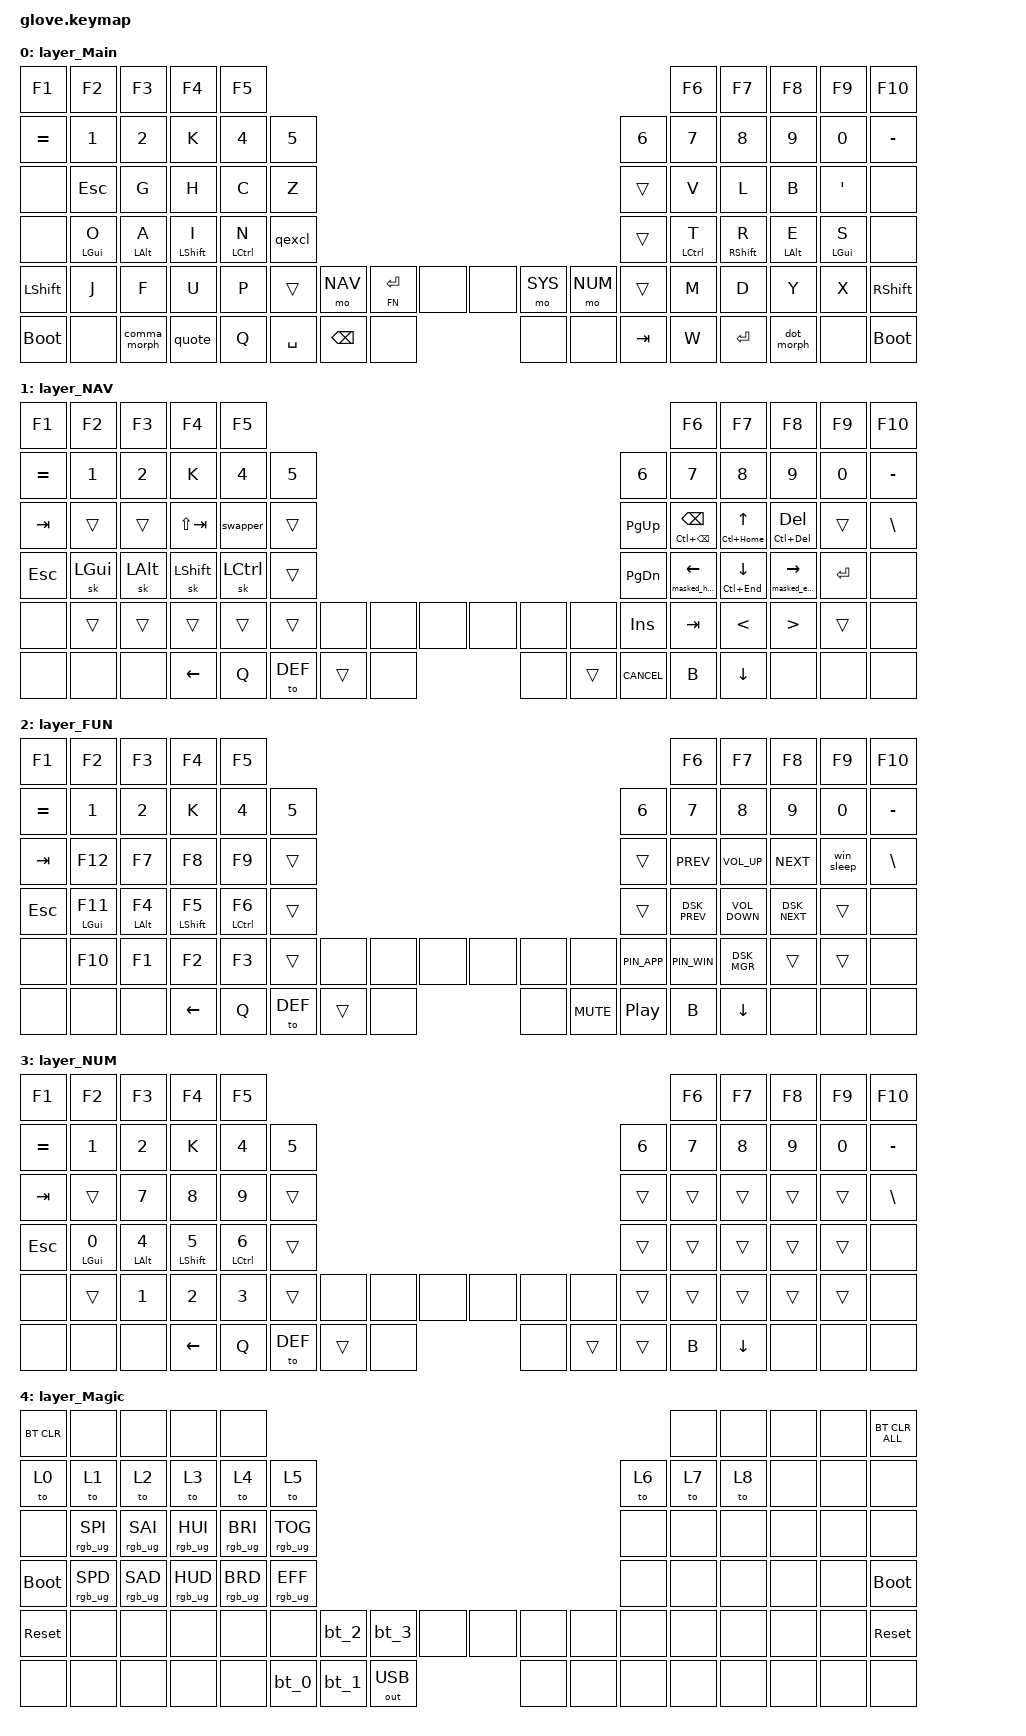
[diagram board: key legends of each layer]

/*
 * Copyright (c) 2020 The ZMK Contributors
 * Copyright (c) 2023 Innaworks Development Limited, trading as MoErgo
 *
 * SPDX-License-Identifier: MIT
 */


/* THIS FILE WAS GENERATED BY GLOVE80 LAYOUT EDITOR
 *
 * This file was generated automatically. You may or may not want to
 * edit it directly.
 */

#include <behaviors.dtsi>
/* Include all behavior includes needed */
#include <dt-bindings/zmk/outputs.h>
#include <dt-bindings/zmk/keys.h>
#include <dt-bindings/zmk/bt.h>
#include <dt-bindings/zmk/rgb.h>

/* Automatically generated layer name #define */
#define LAYER_Main 0
#define LAYER_NAV 1
#define LAYER_FUN 2
#define LAYER_NUM 3
#define LAYER_Magic 4

/* To deal with the situation where there is no Lower layer, to keep &lower happy */
#ifndef LAYER_Lower
#define LAYER_Lower 5
#endif

/* Custom Device-tree */



/* Glove80 system behavior & macros */
/ {
    behaviors {
        // For the "layer" key, it'd nice to be able to use it as either a shift or a toggle.
        // Configure it as a tap dance, so the first tap (or hold) is a &mo and the second tap is a &to
        lower: lower {
            compatible = "zmk,behavior-tap-dance";
            label = "LAYER_TAP_DANCE";
            #binding-cells = <0>;
            tapping-term-ms = <200>;
            bindings = <&mo LAYER_Lower>, <&to LAYER_Lower>;
        };
    };
};

/ {
    macros {
        rgb_ug_status_macro: rgb_ug_status_macro {
            label = "RGB_UG_STATUS";
            compatible = "zmk,behavior-macro";
            #binding-cells = <0>;
            bindings
                = <&rgb_ug RGB_STATUS>;
        };
    };
};


/ {
#ifdef BT_DISC_CMD
    behaviors {
        bt_0: bt_0 {
            compatible = "zmk,behavior-tap-dance";
            label = "BT_0";
            #binding-cells = <0>;
            tapping-term-ms = <200>;
            bindings = <&bt_select_0>, <&bt BT_DISC 0>;
        };
        bt_1: bt_1 {
            compatible = "zmk,behavior-tap-dance";
            label = "BT_1";
            #binding-cells = <0>;
            tapping-term-ms = <200>;
            bindings = <&bt_select_1>, <&bt BT_DISC 1>;
        };
        bt_2: bt_2 {
            compatible = "zmk,behavior-tap-dance";
            label = "BT_2";
            #binding-cells = <0>;
            tapping-term-ms = <200>;
            bindings = <&bt_select_2>, <&bt BT_DISC 2>;
        };
        bt_3: bt_3 {
            compatible = "zmk,behavior-tap-dance";
            label = "BT_3";
            #binding-cells = <0>;
            tapping-term-ms = <200>;
            bindings = <&bt_select_3>, <&bt BT_DISC 3>;
        };
    };
    macros {
        bt_select_0: bt_select_0 {
            label = "BT_SELECT_0";
            compatible = "zmk,behavior-macro";
            #binding-cells = <0>;
            bindings
                = <&out OUT_BLE>,
                  <&bt BT_SEL 0>;
        };
        bt_select_1: bt_select_1 {
            label = "BT_SELECT_1";
            compatible = "zmk,behavior-macro";
            #binding-cells = <0>;
            bindings
                = <&out OUT_BLE>,
                  <&bt BT_SEL 1>;
        };
        bt_select_2: bt_select_2 {
            label = "BT_SELECT_2";
            compatible = "zmk,behavior-macro";
            #binding-cells = <0>;
            bindings
                = <&out OUT_BLE>,
                  <&bt BT_SEL 2>;
        };
        bt_select_3: bt_select_3 {
            label = "BT_SELECT_3";
            compatible = "zmk,behavior-macro";
            #binding-cells = <0>;
            bindings
                = <&out OUT_BLE>,
                  <&bt BT_SEL 3>;
        };
    };
#else
    macros {
        bt_0: bt_0 {
            label = "BT_0";
            compatible = "zmk,behavior-macro";
            #binding-cells = <0>;
            bindings
                = <&out OUT_BLE>,
                  <&bt BT_SEL 0>;
        };
        bt_1: bt_1 {
            label = "BT_1";
            compatible = "zmk,behavior-macro";
            #binding-cells = <0>;
            bindings
                = <&out OUT_BLE>,
                  <&bt BT_SEL 1>;
        };
        bt_2: bt_2 {
            label = "BT_2";
            compatible = "zmk,behavior-macro";
            #binding-cells = <0>;
            bindings
                = <&out OUT_BLE>,
                  <&bt BT_SEL 2>;
        };
        bt_3: bt_3 {
            label = "BT_3";
            compatible = "zmk,behavior-macro";
            #binding-cells = <0>;
            bindings
                = <&out OUT_BLE>,
                  <&bt BT_SEL 3>;
        };
    };
#endif
};

&sk {  // sticky-key config
    release-after-ms = <900>;  // release after 0.6s
    quick-release;             // no double capitalization when rolling keys
};

&sl {  // sticky-layer config
    ignore-modifiers;          // allow chording sticky mods & layers
};

&lt {  // layer-tap config
    flavor = "balanced";
    tapping-term-ms = <200>;
    quick-tap-ms = <QUICK_TAP_MS>;
};

/ {
    behaviors {
        magic: magic {
            compatible = "zmk,behavior-hold-tap";
            label = "MAGIC_HOLD_TAP";
            #binding-cells = <2>;
            flavor = "tap-preferred";
            tapping-term-ms = <200>;
            bindings = <&mo>, <&rgb_ug_status_macro>;
        };
    };
};

/* #define for key positions */
#define POS_LH_T1 52
#define POS_LH_T2 53
#define POS_LH_T3 54
#define POS_LH_T4 69
#define POS_LH_T5 70
#define POS_LH_T6 71
#define POS_LH_C1R2 15
#define POS_LH_C1R3 27
#define POS_LH_C1R4 39
#define POS_LH_C1R5 51
#define POS_LH_C2R1 4
#define POS_LH_C2R2 14
#define POS_LH_C2R3 26
#define POS_LH_C2R4 38
#define POS_LH_C2R5 50
#define POS_LH_C2R6 68
#define POS_LH_C3R1 3
#define POS_LH_C3R2 13
#define POS_LH_C3R3 25
#define POS_LH_C3R4 37
#define POS_LH_C3R5 49
#define POS_LH_C3R6 67
#define POS_LH_C4R1 2
#define POS_LH_C4R2 12
#define POS_LH_C4R3 24
#define POS_LH_C4R4 36
#define POS_LH_C4R5 48
#define POS_LH_C4R6 66
#define POS_LH_C5R1 1
#define POS_LH_C5R2 11
#define POS_LH_C5R3 23
#define POS_LH_C5R4 35
#define POS_LH_C5R5 47
#define POS_LH_C5R6 65
#define POS_LH_C6R1 0
#define POS_LH_C6R2 10
#define POS_LH_C6R3 22
#define POS_LH_C6R4 34
#define POS_LH_C6R5 46
#define POS_LH_C6R6 64
#define POS_RH_T1 57
#define POS_RH_T2 56
#define POS_RH_T3 55
#define POS_RH_T4 74
#define POS_RH_T5 73
#define POS_RH_T6 72
#define POS_RH_C1R2 16
#define POS_RH_C1R3 28
#define POS_RH_C1R4 40
#define POS_RH_C1R5 58
#define POS_RH_C2R1 5
#define POS_RH_C2R2 17
#define POS_RH_C2R3 29
#define POS_RH_C2R4 41
#define POS_RH_C2R5 59
#define POS_RH_C2R6 75
#define POS_RH_C3R1 6
#define POS_RH_C3R2 18
#define POS_RH_C3R3 30
#define POS_RH_C3R4 42
#define POS_RH_C3R5 60
#define POS_RH_C3R6 76
#define POS_RH_C4R1 7
#define POS_RH_C4R2 19
#define POS_RH_C4R3 31
#define POS_RH_C4R4 43
#define POS_RH_C4R5 61
#define POS_RH_C4R6 77
#define POS_RH_C5R1 8
#define POS_RH_C5R2 20
#define POS_RH_C5R3 32
#define POS_RH_C5R4 44
#define POS_RH_C5R5 62
#define POS_RH_C5R6 78
#define POS_RH_C6R1 9
#define POS_RH_C6R2 21
#define POS_RH_C6R3 33
#define POS_RH_C6R4 45
#define POS_RH_C6R5 63
#define POS_RH_C6R6 79

#define LC1  4  // left-ceiling row
#define LC2  3
#define LC3  2
#define LC4  1
#define LC5  0

#define RC1  5  // right-ceiling row
#define RC2  6
#define RC3  7
#define RC4  8
#define RC5  9

#define LN0 15  // left-number row
#define LN1 14
#define LN2 13
#define LN3 12
#define LN4 11
#define LN5 10

#define RN0 16  // right-number row
#define RN1 17
#define RN2 18
#define RN3 19
#define RN4 20
#define RN5 21

#define LT0 27  // left-top row
#define LT1 26
#define LT2 25
#define LT3 24
#define LT4 23
#define LT5 22

#define RT0 28  // right-top row
#define RT1 29
#define RT2 30
#define RT3 31
#define RT4 32
#define RT5 33

#define LM0 39  // left-middle row
#define LM1 38
#define LM2 37
#define LM3 36
#define LM4 35
#define LM5 34

#define RM0 40  // right-middle row
#define RM1 41
#define RM2 42
#define RM3 43
#define RM4 44
#define RM5 45

#define LB0 51  // left-bottom row
#define LB1 50
#define LB2 49
#define LB3 48
#define LB4 47
#define LB5 46

#define RB0 58  // right-bottom row
#define RB1 59
#define RB2 60
#define RB3 61
#define RB4 62
#define RB5 63

#define LF1 68  // left-floor row
#define LF2 67
#define LF3 66
#define LF4 65
#define LF5 64

#define RF1 75  // right-floor row
#define RF2 76
#define RF3 77
#define RF4 78
#define RF5 79

#define LH0 71  // left thumb keys
#define LH1 70
#define LH2 69
#define LH3 54
#define LH4 53
#define LH5 52

#define RH0 72  // right thumb keys
#define RH1 73
#define RH2 74
#define RH3 55
#define RH4 56
#define RH5 57



/* Custom Defined Behaviors */
/ {


behaviors {
        hml: hml { compatible = "zmk,behavior-hold-tap"; #binding-cells = <2>; flavor = "balanced"; tapping-term-ms = <280>; quick-tap-ms = <175>; require-prior-idle-ms = <350>; bindings = <&kp>, <&kp>; hold-trigger-key-positions = <28 29 30 31 32 40 41 42 43 44 58 59 60 61 62 75 76 77 78 79 69 70 71 72 73 74>; hold-trigger-on-release; };
hmr: hmr { compatible = "zmk,behavior-hold-tap"; #binding-cells = <2>; flavor = "balanced"; tapping-term-ms = <280>; quick-tap-ms = <175>; require-prior-idle-ms = <350>; bindings = <&kp>, <&kp>; hold-trigger-key-positions = <27 26 25 24 23 39 38 37 36 35 51 50 49 48 47 68 67 66 65 64 15 14 13 12 11 10 69 70 71 72 73 74>; hold-trigger-on-release; };

hml_repeat: hml_repeat { compatible = "zmk,behavior-hold-tap"; #binding-cells = <2>; flavor = "balanced"; tapping-term-ms = <280>; quick-tap-ms = <175>; require-prior-idle-ms = <350>; bindings = <&kp>, <&key_repeat>; hold-trigger-key-positions = <28 29 30 31 32 40 41 42 43 44 58 59 60 61 62 75 76 77 78 79 69 70 71 72 73 74>; hold-trigger-on-release; };
hmr_lpar_lt: hmr_lpar_lt { compatible = "zmk,behavior-hold-tap"; #binding-cells = <2>; flavor = "balanced"; tapping-term-ms = <280>; quick-tap-ms = <175>; require-prior-idle-ms = <350>; bindings = <&kp>, <&lpar_lt>; hold-trigger-key-positions = <27 26 25 24 23 39 38 37 36 35 51 50 49 48 47 68 67 66 65 64 15 14 13 12 11 10 69 70 71 72 73 74>; hold-trigger-on-release; };
hmr_rpar_gt: hmr_rpar_gt { compatible = "zmk,behavior-hold-tap"; #binding-cells = <2>; flavor = "balanced"; tapping-term-ms = <280>; quick-tap-ms = <175>; require-prior-idle-ms = <350>; bindings = <&kp>, <&rpar_gt>; hold-trigger-key-positions = <27 26 25 24 23 39 38 37 36 35 51 50 49 48 47 68 67 66 65 64 15 14 13 12 11 10 69 70 71 72 73 74>; hold-trigger-on-release; };
# 336 "/app/example.cpp"
&mt { flavor = "tap-preferred"; tapping-term-ms = <220>; quick-tap-ms = <220>; hold-trigger-key-positions = <0>; };
mt_home: mt_home { compatible = "zmk,behavior-hold-tap"; #binding-cells = <2>; bindings = <&masked_home>, <&kp>; flavor = "tap-preferred"; tapping-term-ms = <220>; quick-tap-ms = <220>; hold-trigger-key-positions = <0>; };
mt_end: mt_end { compatible = "zmk,behavior-hold-tap"; #binding-cells = <2>; bindings = <&masked_end>, <&kp>; flavor = "tap-preferred"; tapping-term-ms = <220>; quick-tap-ms = <220>; hold-trigger-key-positions = <0>; };
# 353 "/app/example.cpp"
masked_home: masked_home { compatible = "zmk,behavior-mod-morph"; #binding-cells = <0>; bindings = <&kp HOME>, <&kp HOME>; mods = <(MOD_LCTL)>; };
masked_end: masked_end { compatible = "zmk,behavior-mod-morph"; #binding-cells = <0>; bindings = <&kp END>, <&kp END>; mods = <(MOD_LCTL)>; };

smart_shft: smart_shft { compatible = "zmk,behavior-mod-morph"; #binding-cells = <0>; bindings = <&sk LSHFT>, <&caps_word>; mods = <(MOD_LSFT)>; };

&caps_word {
    /delete-property/ ignore-modifiers;
};

smart_num: smart_num { compatible = "zmk,behavior-hold-tap"; #binding-cells = <2>; flavor = "balanced"; tapping-term-ms = <200>; quick-tap-ms = <175>; bindings = <&mo>, <&num_dance>; };

num_dance: num_dance { compatible = "zmk,behavior-tap-dance"; #binding-cells = <0>; tapping-term-ms = <200>; bindings = <&num_word>, <&sl Layer_NUM>; };

&num_word {
    layers = <Layer_NUM>;
    continue-list = <BSPC DEL DOT COMMA PLUS MINUS STAR FSLH EQUAL>;
};

smart_mouse: smart_mouse { compatible = "zmk,behavior-tri-state"; #binding-cells = <0>; bindings = <&tog MOUSE>, <&none>, <&tog MOUSE>; ignored-key-positions = <26 24 28 29 30 31 32 41 42 43 59 60 61 72 73>; ignored-layers = <MOUSE>; };
# 394 "/app/example.cpp"
swapper: swapper { compatible = "zmk,behavior-tri-state"; #binding-cells = <0>; bindings = <&kt LALT>, <&kp TAB>, <&kt LALT>; ignored-key-positions = <25>; };

sls: sls { compatible = "zmk,behavior-sticky-key"; #binding-cells = <1>; release-after-ms = <1000>; bindings = <&uc_shift>; ignore-modifiers; };

uc_shift: uc_shift { compatible = "zmk,behavior-macro"; #binding-cells = <0>; wait-ms = <0>; tap-ms = <1>; bindings = <&macro_press &mo UC &kp LSHFT> , <&macro_pause_for_release> , <&macro_release &mo UC &kp LSHFT>; };
# 421 "/app/example.cpp"
comma_morph: comma_morph { compatible = "zmk,behavior-mod-morph"; #binding-cells = <0>; mods = <(MOD_LSFT|MOD_RSFT)>; bindings = <&kp COMMA>, <&comma_inner_morph>; };
comma_inner_morph: comma_inner_morph { compatible = "zmk,behavior-mod-morph"; #binding-cells = <0>; mods = <(MOD_LCTL|MOD_RCTL)>; bindings = <&kp SEMICOLON>, <&kp LESS_THAN>; };

dot_morph: dot_morph { compatible = "zmk,behavior-mod-morph"; #binding-cells = <0>; mods = <(MOD_LSFT|MOD_RSFT)>; bindings = <&kp DOT>, <&dot_inner_morph>; };
dot_inner_morph: dot_inner_morph { compatible = "zmk,behavior-mod-morph"; #binding-cells = <0>; mods = <(MOD_LCTL|MOD_RCTL)>; bindings = <&kp COLON>, <&kp GREATER_THAN>; };

qexcl: qexcl { compatible = "zmk,behavior-mod-morph"; #binding-cells = <0>; mods = <(MOD_LSFT|MOD_RSFT)>; bindings = <&kp QMARK>, <&kp EXCL>; };
quote: quote { compatible = "zmk,behavior-mod-morph"; #binding-cells = <0>; mods = <(MOD_LSFT|MOD_RSFT)>; bindings = <&kp LS(SINGLE_QUOTE)>, <&kp SINGLE_QUOTE>; };

lpar_lt: lpar_lt { compatible = "zmk,behavior-mod-morph"; #binding-cells = <0>; mods = <(MOD_LSFT|MOD_RSFT)>; bindings = <&kp LPAR>, <&kp LT>; };
rpar_gt: rpar_gt { compatible = "zmk,behavior-mod-morph"; #binding-cells = <0>; mods = <(MOD_LSFT|MOD_RSFT)>; bindings = <&kp RPAR>, <&kp GT>; };

lt_spc: lt_spc { compatible = "zmk,behavior-hold-tap"; #binding-cells = <2>; flavor = "balanced"; tapping-term-ms = <200>; quick-tap-ms = <175>; bindings = <&mo>, <&spc_morph>; };

spc_morph: spc_morph { compatible = "zmk,behavior-mod-morph"; #binding-cells = <0>; mods = <(MOD_LSFT|MOD_RSFT)>; bindings = <&kp SPACE>, <&dot_spc>; };
dot_spc: dot_spc { compatible = "zmk,behavior-macro"; #binding-cells = <0>; wait-ms = <0>; tap-ms = <5>; bindings = <&kp DOT &kp SPACE &sk LSHFT>; };

bs_del: bs_del { compatible = "zmk,behavior-mod-morph"; #binding-cells = <0>; bindings = <&kp BSPC>, <&kp DEL>; mods = <(MOD_LSFT|MOD_RSFT)>; keep-mods = <MOD_RSFT>; };

copy_cut: copy_cut { compatible = "zmk,behavior-tap-dance"; #binding-cells = <0>; tapping-term-ms = <200>; bindings = <&kp LC(INS)>, <&kp LC(X)>; };

win_sleep: win_sleep { compatible = "zmk,behavior-macro"; #binding-cells = <0>; wait-ms = <500>; tap-ms = <50>; bindings = <&kp LG(X) &kp U &kp S>; };
};


/ { conditional_layers { compatible = "zmk,conditional-layers"; tri_layer { if-layers = <FN Layer_NUM>; then-layer = <SYS>; }; }; };

    //
    // Glove80 key positions index for positional hold-tap
    // - https://discord.com/channels/877392805654306816/937645688244826154/1066713913351221248
    // - https://media.discordapp.net/attachments/937645688244826154/1066713913133121556/image.png
    //
    // |------------------------|------------------------|
    // | LEFT_HAND_KEYS         |        RIGHT_HAND_KEYS |
    // |                        |                        |
    // |  0  1  2  3  4         |          5  6  7  8  9 |
    // | 10 11 12 13 14 15      |      16 17 18 19 20 21 |
    // | 22 23 24 25 26 27      |      28 29 30 31 32 33 |
    // | 34 35 36 37 38 39      |      40 41 42 43 44 45 |
    // | 46 47 48 49 50 51      |      58 59 60 61 62 63 |
    // | 64 65 66 67 68         |         75 76 77 78 79 |
    // |                69 52   |   57 74                |
    // |                 70 53  |  56 73                 |
    // |                  71 54 | 55 72                  |
    // |------------------------|------------------------|
    //

macros {



  // Function arrow: ->
  func_arrow: function_arrow {
    compatible = "zmk,behavior-macro";
    label = "FUNCTION_ARROW";
    #binding-cells = <0>;
    tap-ms = <0>;
    wait-ms = <0>;
    bindings
    = <&macro_tap &kp MINUS &kp GREATER_THAN>
    ;
  };

  and_short: and_short{
    compatible = "zmk,behavior-macro";
    label = "AND_SHORT";
    #binding-cells = <0>;
    tap-ms = <0>;
    wait-ms = <0>;
    bindings
    = <&macro_tap &kp AMPERSAND &kp AMPERSAND>
    ;
  };

  or_short: or_short{
    compatible = "zmk,behavior-macro";
    label = "OR_SHORT";
    #binding-cells = <0>;
    tap-ms = <0>;
    wait-ms = <0>;
    bindings
    = <&macro_tap &kp PIPE &kp PIPE>
    ;
  };

  neq_short: neq_short{
    compatible = "zmk,behavior-macro";
    label = "NEQ_SHORT";
    #binding-cells = <0>;
    tap-ms = <0>;
    wait-ms = <0>;
    bindings
    = <&macro_tap &kp EXCLAMATION &kp EQUAL>
    ;
  };

  eq_short: eq_short{
      compatible = "zmk,behavior-macro";
      label = "EQ_SHORT";
      #binding-cells = <0>;
      tap-ms = <0>;
      wait-ms = <0>;
      bindings
      = <&macro_tap &kp EQUAL &kp EQUAL>
      ;
    };
};
combos {
    compatible = "zmk,combos";
 combo_esc { timeout-ms = <18>; bindings = <&kp ESC>; key-positions = <24 25>; layers = <Layer_Main Layer_NAV Layer_NUM>; require-prior-idle-ms = <150>; };
 combo_ret { timeout-ms = <18>; bindings = <&kp RETURN>; key-positions = <25 26>; layers = <Layer_Main Layer_NAV Layer_NUM>; require-prior-idle-ms = <150>; };
 combo_mouse { timeout-ms = <18>; bindings = <&smart_mouse>; key-positions = <24 26>; layers = <Layer_Main Layer_NAV Layer_NUM>; require-prior-idle-ms = <150>; };
 combo_tab { timeout-ms = <18>; bindings = <&hml LS(LALT) TAB>; key-positions = <36 37>; layers = <Layer_Main Layer_NAV Layer_NUM>; require-prior-idle-ms = <150>; };
 combo_repeat { timeout-ms = <18>; bindings = <&hml_repeat LS(LCTRL) 0>; key-positions = <37 38>; layers = <Layer_Main Layer_NAV Layer_NUM>; require-prior-idle-ms = <150>; };
 combo_cut { timeout-ms = <18>; bindings = <&kp LC(X)>; key-positions = <48 50>; layers = <Layer_Main Layer_NAV Layer_NUM>; require-prior-idle-ms = <150>; };
 combo_copy { timeout-ms = <18>; bindings = <&kp LC(INS)>; key-positions = <48 49>; layers = <Layer_Main Layer_NAV Layer_NUM>; require-prior-idle-ms = <150>; };
 combo_paste { timeout-ms = <18>; bindings = <&kp LS(INS)>; key-positions = <49 50>; layers = <Layer_Main Layer_NAV Layer_NUM>; require-prior-idle-ms = <150>; };
 combo_bspc { timeout-ms = <18>; bindings = <&kp BSPC>; key-positions = <29 30>; layers = <Layer_Main Layer_NAV Layer_NUM>; require-prior-idle-ms = <150>; };
 combo_del { timeout-ms = <18>; bindings = <&kp DEL>; key-positions = <30 31>; layers = <Layer_Main Layer_NAV Layer_NUM>; require-prior-idle-ms = <150>; };
 combo_lpar { timeout-ms = <18>; bindings = <&hmr_lpar_lt RS(LCTRL) 0>; key-positions = <41 42>; layers = <Layer_Main Layer_NUM>; require-prior-idle-ms = <150>; };
 combo_rpar { timeout-ms = <18>; bindings = <&hmr_rpar_gt RS(LALT) 0>; key-positions = <42 43>; layers = <Layer_Main Layer_NUM>; require-prior-idle-ms = <150>; };
 combo_lt { timeout-ms = <18>; bindings = <&kp LT>; key-positions = <41 42>; layers = <Layer_NAV>; require-prior-idle-ms = <150>; };
 combo_gt { timeout-ms = <18>; bindings = <&kp GT>; key-positions = <42 43>; layers = <Layer_NAV>; require-prior-idle-ms = <150>; };
 combo_lbkt { timeout-ms = <18>; bindings = <&kp LBKT>; key-positions = <59 60>; layers = <Layer_Main Layer_NUM>; require-prior-idle-ms = <150>; };
 combo_rbkt { timeout-ms = <18>; bindings = <&kp RBKT>; key-positions = <60 61>; layers = <Layer_Main Layer_NUM>; require-prior-idle-ms = <150>; };
 combo_lbrc { timeout-ms = <18>; bindings = <&kp LBRC>; key-positions = <59 60>; layers = <Layer_NAV>; require-prior-idle-ms = <150>; };
 combo_rbrc { timeout-ms = <18>; bindings = <&kp RBRC>; key-positions = <60 61>; layers = <Layer_NAV>; require-prior-idle-ms = <150>; };
 combo_grk { timeout-ms = <18>; bindings = <&sl UC>; key-positions = <29 31>; layers = <Layer_Main Layer_NAV Layer_NUM>; require-prior-idle-ms = <150>; };
 combo_cpgrk { timeout-ms = <18>; bindings = <&sls 0>; key-positions = <29 30 31>; layers = <Layer_Main Layer_NAV Layer_NUM>; require-prior-idle-ms = <150>; };
 combo_at { timeout-ms = <30>; bindings = <&kp AT>; key-positions = <24 36>; layers = <Layer_Main Layer_NAV Layer_NUM>; require-prior-idle-ms = <50>; };
 combo_hash { timeout-ms = <30>; bindings = <&kp HASH>; key-positions = <25 37>; layers = <Layer_Main Layer_NAV Layer_NUM>; require-prior-idle-ms = <50>; };
 combo_dllr { timeout-ms = <30>; bindings = <&kp DLLR>; key-positions = <26 38>; layers = <Layer_Main Layer_NAV Layer_NUM>; require-prior-idle-ms = <50>; };
 combo_prcnt { timeout-ms = <30>; bindings = <&kp PRCNT>; key-positions = <27 39>; layers = <Layer_Main Layer_NAV Layer_NUM>; require-prior-idle-ms = <50>; };
 combo_grave { timeout-ms = <30>; bindings = <&kp GRAVE>; key-positions = <36 48>; layers = <Layer_Main Layer_NAV Layer_NUM>; require-prior-idle-ms = <50>; };
 combo_bslh { timeout-ms = <30>; bindings = <&kp BSLH>; key-positions = <37 49>; layers = <Layer_Main Layer_NAV Layer_NUM>; require-prior-idle-ms = <50>; };
 combo_equal { timeout-ms = <30>; bindings = <&kp EQUAL>; key-positions = <38 50>; layers = <Layer_Main Layer_NAV Layer_NUM>; require-prior-idle-ms = <50>; };
 combo_tilde { timeout-ms = <30>; bindings = <&kp TILDE>; key-positions = <39 51>; layers = <Layer_Main Layer_NAV Layer_NUM>; require-prior-idle-ms = <50>; };
 combo_caret { timeout-ms = <30>; bindings = <&kp CARET>; key-positions = <28 40>; layers = <Layer_Main Layer_NAV Layer_NUM>; require-prior-idle-ms = <50>; };
 combo_plus { timeout-ms = <30>; bindings = <&kp PLUS>; key-positions = <29 41>; layers = <Layer_Main Layer_NAV Layer_NUM>; require-prior-idle-ms = <50>; };
 combo_star { timeout-ms = <30>; bindings = <&kp STAR>; key-positions = <30 42>; layers = <Layer_Main Layer_NAV Layer_NUM>; require-prior-idle-ms = <50>; };
 combo_amps { timeout-ms = <30>; bindings = <&kp AMPS>; key-positions = <31 43>; layers = <Layer_Main Layer_NAV Layer_NUM>; require-prior-idle-ms = <50>; };
 combo_under { timeout-ms = <30>; bindings = <&kp UNDER>; key-positions = <40 58>; layers = <Layer_Main Layer_NAV Layer_NUM>; require-prior-idle-ms = <50>; };
 combo_minus { timeout-ms = <30>; bindings = <&kp MINUS>; key-positions = <41 59>; layers = <Layer_Main Layer_NAV Layer_NUM>; require-prior-idle-ms = <50>; };
 combo_fslh { timeout-ms = <30>; bindings = <&kp FSLH>; key-positions = <42 60>; layers = <Layer_Main Layer_NAV Layer_NUM>; require-prior-idle-ms = <50>; };
 combo_pipe { timeout-ms = <30>; bindings = <&kp PIPE>; key-positions = <43 61>; layers = <Layer_Main Layer_NAV Layer_NUM>; require-prior-idle-ms = <50>; };
};

};

/* Automatically generated macro definitions */
/ {
    macros {
    
    };
};


/* Automatically generated keymap */
/ {
    keymap {
        compatible = "zmk,keymap";


        layer_Main {
            bindings = <
    //╭─────────────┬─────────────┬─────────────┬─────────────┬─────────────╮                                                                                                            ╭─────────────┬─────────────┬─────────────┬──────────────┬─────────────╮
     &kp F1         &kp F2        &kp F3       &kp F4        &kp F5                                                                                                                    &kp F6        &kp F7        &kp F8        &kp F9        &kp F10 
//├─────────────┼─────────────┼─────────────┼─────────────┼─────────────┼───────────╮                                                                                 ╭──────────────┼─────────────┼─────────────┼─────────────┼──────────────┼─────────────┤
     &kp EQUAL      &kp N1        &kp N2       &kp K         &kp N4        &kp N5                                                                                       &kp N6         &kp N7        &kp N8        &kp N9        &kp N0        &kp MINUS                
//╰─────────────┴─────────────┴─────────────┴─────────────┴─────────────┴───────────╯                                                                                 ╰──────────────┴─────────────┴─────────────┴─────────────┴──────────────┴─────────────╯
         
//╭─────────────┬──────────────┬─────────────┬─────────────┬─────────────┬────────────╮                                                                               ╭─────────────┬─────────────┬─────────────┬─────────────┬──────────────┬──────────────╮
    &none         &kp ESC        &kp G         &kp H         &kp C          &kp Z                                                                                          &trans       &kp V         &kp L         &kp B         &kp SQT       &none  
//├─────────────┤──────────────┼─────────────┼─────────────┼─────────────┼────────────┤                                                                               ├─────────────┼─────────────┼─────────────┼─────────────┼──────────────┼──────────────┤
    &none         &hml LGUI O    &hml LALT A   &hml LSHFT I  &hml LCTRL N   &qexcl                                                                                         &trans       &hmr LCTRL T  &hmr RSHFT R  &hmr LALT E   &hmr LGUI S   &none  
//├─────────────┤──────────────┼─────────────┼─────────────┼─────────────┼────────────┤ ╭──────────────┬─────────────┬───────╮╭────────┬──────────────┬─────────────╮ ├─────────────┼─────────────┼─────────────┼─────────────┼──────────────┼──────────────┤
    &kp LSHFT     &kp J          &kp F         &kp U         &kp P          &trans         &mo NAV       &lt FN RET    &none    &none     &mo SYS       &mo NUM           &trans        &kp M         &kp D         &kp Y         &kp X         &kp RSHFT  
//├─────────────┼──────────────┤─────────────┼─────────────┤─────────────┼────────────╯ ├──────────────┼─────────────┼───────┤├────────┼──────────────┼─────────────┤ ╰─────────────┼─────────────┼─────────────┤─────────────┼──────────────┤──────────────┤
    &bootloader   &none         &comma_morph   &quote        &kp Q                         &kp SPACE     &kp BACKSPACE &none    &none     &none         &kp TAB                         &kp W         &kp RET      &dot_morph     &none         &bootloader
//╰─────────────┴──────────────┴─────────────┴─────────────┴─────────────╯              ╰──────────────┴─────────────┴───────╯╰────────┴──────────────┴─────────────╯               ╰─────────────┴─────────────┴─────────────┴──────────────┴──────────────╯                                           
           >;
        };

        layer_NAV {      
                    bindings = <             
//╭──────╮ ╭─────────────┬─────────────┬─────────────┬─────────────┬─────────────╮ ╭──────╮ ╭─────────────┬─────────────┬─────────────┬─────────────┬─────────────╮ ╭──────╮
    \
                &kp F1    &kp F2 &kp F3 &kp F4 &kp F5                 &kp F6 &kp F7 &kp F8 &kp F9 &kp F10 \
                &kp EQUAL &kp N1 &kp N2 &kp K &kp N4 &kp N5   &kp N6 &kp N7 &kp N8 &kp N9 &kp N0 &kp MINUS \
                &kp TAB     &trans           &trans           &kp LS(TAB)   &swapper      &trans           &kp PG_UP     &mt LC(BSPC) BSPC       &mt LC(HOME) UP         &mt LC(DEL)  DEL       &trans             &kp BACKSLASH
//├──────┤ ├─────────────┼─────────────┼─────────────┼─────────────┼─────────────┤ ├──────┤ ├─────────────┼─────────────┼─────────────┼─────────────┼─────────────┤ ├──────┤
    &kp ESC     &sk LGUI      &sk LALT      &sk LSHFT     &sk LCTRL     &trans                &kp PG_DN     &mt_home 0   LEFT      &mt LC(END)  DOWN       &mt_end 0    RIGHT     &kp RET         &none
//├──────┤ ├─────────────┼─────────────┼─────────────┼─────────────┼─────────────┤ ├──────┤ ├─────────────┼─────────────┼─────────────┼─────────────┼─────────────┤ ├──────┤
    &none     &trans           &trans           &trans           &trans           &trans             &none &none &none       &none &none &none     &kp INS       &kp TAB       &kp LT        &kp GT        &trans             &none
//├──────┤ ╰─────────────┼─────────────┴─────────────┼─────────────┼─────────────┤ ├──────┤ ├─────────────┼─────────────┼─────────────┴───────────────────────────╯ ├──────┤
    &none &none &none &kp LEFT &kp Q                                               &to DEF           &trans              &none &none     &trans           CANCEL                                                    &kp B &kp DOWN &none &none &none
//╰──────╯                                           ╰─────────────┴─────────────╯ ╰──────╯ ╰─────────────┴─────────────╯                                           ╰──────╯

>;
        };

        layer_FUN {   
                    bindings = <
//╭──────╮ ╭─────────────┬─────────────┬─────────────┬─────────────┬─────────────╮ ╭──────╮ ╭─────────────┬─────────────┬─────────────┬─────────────┬─────────────╮ ╭──────╮
    \
                &kp F1    &kp F2 &kp F3 &kp F4 &kp F5                 &kp F6 &kp F7 &kp F8 &kp F9 &kp F10 \
                &kp EQUAL &kp N1 &kp N2 &kp K &kp N4 &kp N5   &kp N6 &kp N7 &kp N8 &kp N9 &kp N0 &kp MINUS \
                &kp TAB     &kp F12       &kp F7        &kp F8        &kp F9        &trans                  &trans           &kp C_PREV    &kp C_VOL_UP  &kp C_NEXT    &win_sleep      &kp BACKSLASH
//├──────┤ ├─────────────┼─────────────┼─────────────┼─────────────┼─────────────┤ ├──────┤ ├─────────────┼─────────────┼─────────────┼─────────────┼─────────────┤ ├──────┤
    &kp ESC     &hml LGUI F11 &hml LALT F4  &hml LSHFT F5 &hml LCTRL F6 &trans                  &trans           DSK_PREV      VOL_DOWN      DSK_NEXT      &trans             &none
//├──────┤ ├─────────────┼─────────────┼─────────────┼─────────────┼─────────────┤ ├──────┤ ├─────────────┼─────────────┼─────────────┼─────────────┼─────────────┤ ├──────┤
    &none     &kp F10       &kp F1        &kp F2        &kp F3        &trans             &none &none &none       &none &none &none     PIN_APP       PIN_WIN       DSK_MGR       &trans           &trans             &none
//├──────┤ ╰─────────────┼─────────────┴─────────────┼─────────────┼─────────────┤ ├──────┤ ├─────────────┼─────────────┼─────────────┴───────────────────────────╯ ├──────┤
    &none &none &none &kp LEFT &kp Q                                               &to DEF           &trans              &none &none     &kp C_MUTE    &kp C_PP                                                  &kp B &kp DOWN &none &none &none
//╰──────╯                                           ╰─────────────┴─────────────╯ ╰──────╯ ╰─────────────┴─────────────╯                                           ╰──────╯
>;
        };

        layer_NUM {  
                    bindings = <
//╭──────╮ ╭─────────────┬─────────────┬─────────────┬─────────────┬─────────────╮ ╭──────╮ ╭─────────────┬─────────────┬─────────────┬─────────────┬─────────────╮ ╭──────╮
    \
                &kp F1    &kp F2 &kp F3 &kp F4 &kp F5                 &kp F6 &kp F7 &kp F8 &kp F9 &kp F10 \
                &kp EQUAL &kp N1 &kp N2 &kp K &kp N4 &kp N5   &kp N6 &kp N7 &kp N8 &kp N9 &kp N0 &kp MINUS \
                &kp TAB     &trans           &kp N7        &kp N8        &kp N9        &trans                  &trans           &trans           &trans           &trans           &trans             &kp BACKSLASH
//├──────┤ ├─────────────┼─────────────┼─────────────┼─────────────┼─────────────┤ ├──────┤ ├─────────────┼─────────────┼─────────────┼─────────────┼─────────────┤ ├──────┤
    &kp ESC     &hml LGUI N0  &hml LALT N4  &hml LSHFT N5 &hml LCTRL N6 &trans                  &trans           &trans           &trans           &trans           &trans             &none
//├──────┤ ├─────────────┼─────────────┼─────────────┼─────────────┼─────────────┤ ├──────┤ ├─────────────┼─────────────┼─────────────┼─────────────┼─────────────┤ ├──────┤
    &none     &trans           &kp N1        &kp N2        &kp N3        &trans             &none &none &none       &none &none &none     &trans           &trans           &trans           &trans           &trans             &none
//├──────┤ ╰─────────────┼─────────────┴─────────────┼─────────────┼─────────────┤ ├──────┤ ├─────────────┼─────────────┼─────────────┴───────────────────────────╯ ├──────┤
    &none &none &none &kp LEFT &kp Q                                               &to DEF           &trans              &none &none     &trans           &trans                                                       &kp B &kp DOWN &none &none &none
//╰──────╯                                           ╰─────────────┴─────────────╯ ╰──────╯ ╰─────────────┴─────────────╯                                           ╰──────╯
>;
        };

        layer_Magic {
            bindings = <
  &bt BT_CLR            &none            &none            &none            &none                                                                                  &none   &none   &none   &none  &bt BT_CLR_ALL
       &to 0            &to 1            &to 2            &to 3            &to 4            &to 5                                                         &to 6   &to 7   &to 8   &none   &none           &none
       &none  &rgb_ug RGB_SPI  &rgb_ug RGB_SAI  &rgb_ug RGB_HUI  &rgb_ug RGB_BRI  &rgb_ug RGB_TOG                                                         &none   &none   &none   &none   &none           &none
 &bootloader  &rgb_ug RGB_SPD  &rgb_ug RGB_SAD  &rgb_ug RGB_HUD  &rgb_ug RGB_BRD  &rgb_ug RGB_EFF                                                         &none   &none   &none   &none   &none     &bootloader
  &sys_reset            &none            &none            &none            &none            &none   &bt_2   &bt_3         &none   &none   &none   &none   &none   &none   &none   &none   &none      &sys_reset
       &none            &none            &none            &none            &none                    &bt_0   &bt_1  &out OUT_USB   &none   &none   &none           &none   &none   &none   &none           &none
            >;
        };

    };
};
